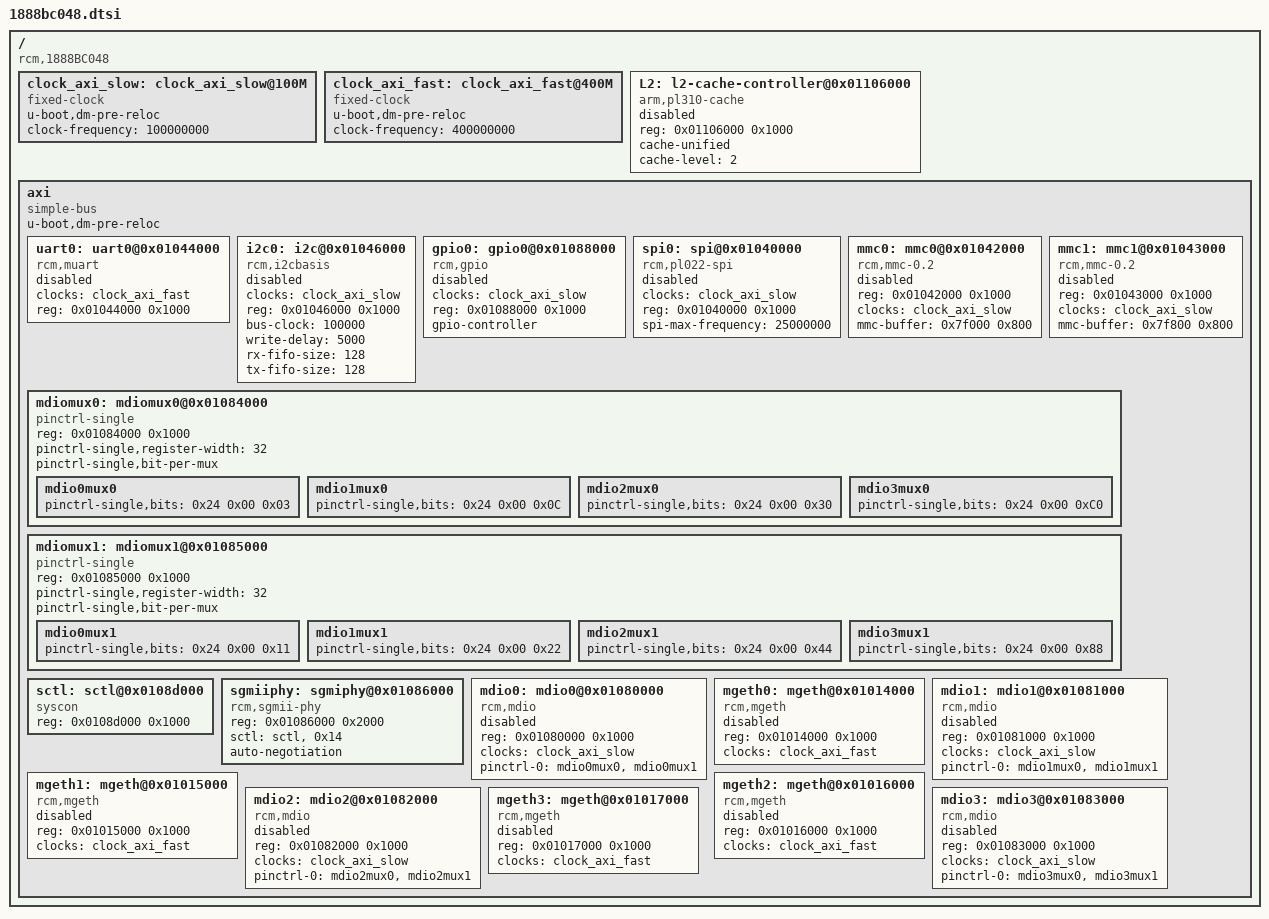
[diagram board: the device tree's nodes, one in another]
/*
 * Device Tree Source for RCM 1888BC048 platform
 *
 * This file is licensed under the terms of the GNU General Public
 * License version 2.  This program is licensed "as is" without
 * any warranty of any kind, whether express or implied.
 */

/dts-v1/;

/ {
	compatible = "rcm,1888BC048";
	#address-cells = <1>;
	#size-cells = <1>;

	clock_axi_slow: clock_axi_slow@100M {
		u-boot,dm-pre-reloc;
		#clock-cells = <0>;
		compatible = "fixed-clock";
		clock-frequency = <100000000>;
	};

	clock_axi_fast: clock_axi_fast@400M {
		u-boot,dm-pre-reloc;
		#clock-cells = <0>;
		compatible = "fixed-clock";
		clock-frequency = <400000000>;
	};

	L2: l2-cache-controller@0x01106000 {
		status = "disabled";
		compatible = "arm,pl310-cache";
		reg = <0x01106000 0x1000>;
		cache-unified;
		cache-level = <2>;
	};	

	axi {
		u-boot,dm-pre-reloc;
		compatible = "simple-bus";
		#address-cells = <1>;
		#size-cells = <1>;

		uart0: uart0@0x01044000 {
			status = "disabled";
			compatible = "rcm,muart";			
			clocks = <&clock_axi_fast>;
			reg = <0x01044000 0x1000>;
		};

		i2c0: i2c@0x01046000 {
			status = "disabled";
			compatible = "rcm,i2cbasis";
			#address-cells = <1>;
			#size-cells = <0>;
			clocks = <&clock_axi_slow>;
			reg = <0x01046000 0x1000>;
			bus-clock = <100000>;
			write-delay = <5000>;
			rx-fifo-size = <128>;
			tx-fifo-size = <128>;
		};

		gpio0: gpio0@0x01088000 {
			status = "disabled";
			compatible = "rcm,gpio";
			#address-cells = <1>;
			#size-cells = <0>;
			clocks = <&clock_axi_slow>;
			reg = <0x01088000 0x1000>;
			#gpio-cells = <2>;
			gpio-controller;
		};

		spi0: spi@0x01040000 {
			status = "disabled";
			compatible = "rcm,pl022-spi";
			#address-cells = <1>;
			#size-cells = <0>;
			clocks = <&clock_axi_slow>;
			reg = <0x01040000 0x1000>;
			spi-max-frequency = <25000000>;		
		};

		mmc0: mmc0@0x01042000 {
			status = "disabled";
			compatible = "rcm,mmc-0.2";
			reg = <0x01042000 0x1000>;
			clocks = <&clock_axi_slow>;
			mmc-buffer = <0x7f000 0x800>;
		};

		mmc1: mmc1@0x01043000 {
			status = "disabled";
			compatible = "rcm,mmc-0.2";
			reg = <0x01043000 0x1000>;
			clocks = <&clock_axi_slow>;
			mmc-buffer = <0x7f800 0x800>;
		};

		mdiomux0: mdiomux0@0x01084000 {
			compatible = "pinctrl-single";
			reg = <0x01084000 0x1000>;
			pinctrl-single,register-width = <32>;
			#address-cells = <1>;
			#size-cells = <0>;
			#pinctrl-cells = <2>;
			pinctrl-single,bit-per-mux;
			mdio0mux0: mdio0mux0 {
				pinctrl-single,bits = <0x24 0x00 0x03>;
			};
			mdio1mux0: mdio1mux0 {
				pinctrl-single,bits = <0x24 0x00 0x0C>;
			};
			mdio2mux0: mdio2mux0 {
				pinctrl-single,bits = <0x24 0x00 0x30>;
			};
			mdio3mux0: mdio3mux0 {
				pinctrl-single,bits = <0x24 0x00 0xC0>;
			};
		};

		mdiomux1: mdiomux1@0x01085000 {
			compatible = "pinctrl-single";
			reg = <0x01085000 0x1000>;
			pinctrl-single,register-width = <32>;
			#address-cells = <1>;
			#size-cells = <0>;
			#pinctrl-cells = <2>;
			pinctrl-single,bit-per-mux;
			mdio0mux1: mdio0mux1 {
				pinctrl-single,bits = <0x24 0x00 0x11>;
			};
			mdio1mux1: mdio1mux1 {
				pinctrl-single,bits = <0x24 0x00 0x22>;
			};
			mdio2mux1: mdio2mux1 {
				pinctrl-single,bits = <0x24 0x00 0x44>;
			};
			mdio3mux1: mdio3mux1 {
				pinctrl-single,bits = <0x24 0x00 0x88>;
			};
		};

		sctl: sctl@0x0108d000 {
			compatible = "syscon";
			reg = <0x0108d000 0x1000>;
			#address-cells = <1>;
			#size-cells = <1>;			
		};

		sgmiiphy: sgmiphy@0x01086000 {
			compatible = "rcm,sgmii-phy";
			reg = <0x01086000 0x2000>;
			#phy-cells = <0>;
			sctl = <&sctl>, <0x14>;
			auto-negotiation;
		};

		mdio0: mdio0@0x01080000 {
			status = "disabled";
			compatible = "rcm,mdio";
			reg = <0x01080000 0x1000>;
			#address-cells = <1>;
			#size-cells = <0>;			
			clocks = <&clock_axi_slow>;		
			pinctrl-names = "default";
			pinctrl-0 = <&mdio0mux0>, <&mdio0mux1>;
		};

		mgeth0: mgeth@0x01014000 {
			status = "disabled";
			compatible = "rcm,mgeth";
			reg = <0x01014000 0x1000>;
			clocks = <&clock_axi_fast>;
		};		

		mdio1: mdio1@0x01081000 {
			status = "disabled";
			compatible = "rcm,mdio";
			reg = <0x01081000 0x1000>;
			#address-cells = <1>;
			#size-cells = <0>;			
			clocks = <&clock_axi_slow>;		
			pinctrl-names = "default";
			pinctrl-0 = <&mdio1mux0>, <&mdio1mux1>;
		};

		mgeth1: mgeth@0x01015000 {
			status = "disabled";
			compatible = "rcm,mgeth";
			reg = <0x01015000 0x1000>;
			clocks = <&clock_axi_fast>;
		};		

		mdio2: mdio2@0x01082000 {
			status = "disabled";
			compatible = "rcm,mdio";
			reg = <0x01082000 0x1000>;
			#address-cells = <1>;
			#size-cells = <0>;			
			clocks = <&clock_axi_slow>;		
			pinctrl-names = "default";
			pinctrl-0 = <&mdio2mux0>, <&mdio2mux1>;
		};

		mgeth2: mgeth@0x01016000 {
			status = "disabled";
			compatible = "rcm,mgeth";
			reg = <0x01016000 0x1000>;
			clocks = <&clock_axi_fast>;
		};		

		mdio3: mdio3@0x01083000 {
			status = "disabled";
			compatible = "rcm,mdio";
			reg = <0x01083000 0x1000>;
			#address-cells = <1>;
			#size-cells = <0>;			
			clocks = <&clock_axi_slow>;		
			pinctrl-names = "default";
			pinctrl-0 = <&mdio3mux0>, <&mdio3mux1>;
		};

		mgeth3: mgeth@0x01017000 {
			status = "disabled";
			compatible = "rcm,mgeth";
			reg = <0x01017000 0x1000>;
			clocks = <&clock_axi_fast>;
		};		
	};
};
